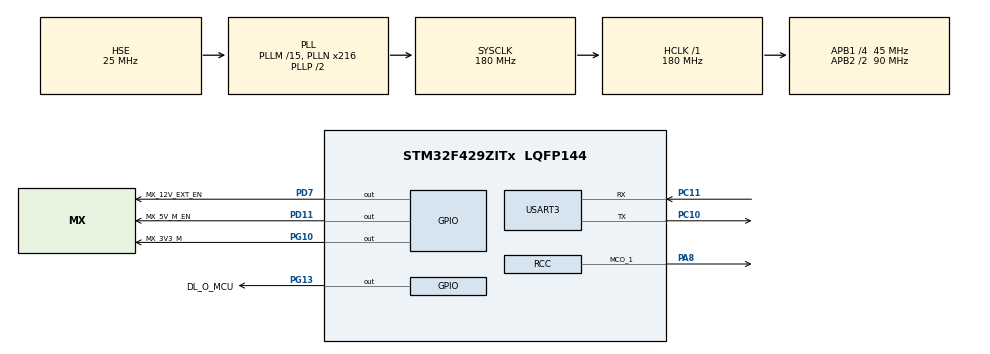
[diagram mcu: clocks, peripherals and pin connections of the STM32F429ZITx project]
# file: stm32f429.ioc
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Mcu.Family=STM32F4
Mcu.Name=STM32F429ZITx
Mcu.Package=LQFP144
NVIC.PriorityGroup=NVIC_PRIORITYGROUP_4
NVIC.TIM6_DAC_IRQn=true\:15\:0\:false\:false\:true\:false\:true
NVIC.TimeBase=TIM6_DAC_IRQn
NVIC.TimeBaseIP=TIM6
NVIC.USART3_IRQn=true\:0\:0\:false\:false\:true\:true\:true
PA13.Mode=Serial_Wire
PA13.Signal=SYS_JTMS-SWDIO
PA14.Mode=Serial_Wire
PA14.Signal=SYS_JTCK-SWCLK
PA8.Mode=Clock-out-1
PA8.Signal=RCC_MCO_1
PC10.Mode=Asynchronous
PC10.Signal=USART3_TX
PC11.Mode=Asynchronous
PC11.Signal=USART3_RX
PD11.GPIO_Label=MX_5V_M_EN
PD11.PinState=GPIO_PIN_SET
PD11.Signal=GPIO_Output
PD7.GPIO_Label=MX_12V_EXT_EN
PD7.PinState=GPIO_PIN_SET
PD7.Signal=GPIO_Output
PG10.GPIO_Label=MX_3V3_M
PG10.GPIO_Speed=GPIO_SPEED_FREQ_LOW
PG10.PinState=GPIO_PIN_SET
PG10.Signal=GPIO_Output
PG13.GPIO_Label=DL_O_MCU
PG13.GPIO_Speed=GPIO_SPEED_FREQ_LOW
PG13.PinState=GPIO_PIN_SET
PG13.Signal=GPIO_Output
PH0/OSC_IN.Mode=HSE-External-Oscillator
PH0/OSC_IN.Signal=RCC_OSC_IN
PH1/OSC_OUT.Mode=HSE-External-Oscillator
PH1/OSC_OUT.Signal=RCC_OSC_OUT
ProjectManager.HeapSize=0x4000
ProjectManager.StackSize=0x1000
ProjectManager.TargetToolchain=Makefile
RCC.48MHZClocksFreq_Value=90000000
RCC.AHBFreq_Value=180000000
RCC.APB1CLKDivider=RCC_HCLK_DIV4
RCC.APB1Freq_Value=45000000
RCC.APB1TimFreq_Value=90000000
RCC.APB2CLKDivider=RCC_HCLK_DIV2
RCC.APB2Freq_Value=90000000
RCC.APB2TimFreq_Value=180000000
RCC.CortexFreq_Value=180000000
RCC.HCLKFreq_Value=180000000
RCC.HSE_VALUE=25000000
RCC.HSI_VALUE=16000000
RCC.LSE_VALUE=32768
RCC.PLLM=15
RCC.PLLN=216
RCC.PLLSourceVirtual=RCC_PLLSOURCE_HSE
RCC.RCC_MCO1Source=RCC_MCO1SOURCE_HSE
RCC.SYSCLKFreq_VALUE=180000000
RCC.SYSCLKSource=RCC_SYSCLKSOURCE_PLLCLK
RCC.VCOOutputFreq_Value=360000000
USART3.VirtualMode=VM_ASYNC
VP_SYS_VS_tim6.Mode=TIM6
board=custom

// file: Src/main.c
/* USER CODE BEGIN Header */
/**
  ******************************************************************************
  * @file           : main.c
  * @brief          : Main program body
  ******************************************************************************
  * @attention
  *
  * Copyright (c) 2021 STMicroelectronics.
  * All rights reserved.
  *
  * This software is licensed under terms that can be found in the LICENSE file
  * in the root directory of this software component.
  * If no LICENSE file comes with this software, it is provided AS-IS.
  *
  ******************************************************************************
  */
/* USER CODE END Header */
#include "main.h"
#include "usart.h"
#include "gpio.h"

/* USER CODE BEGIN Includes */
#include <stdio.h>
#include <errno.h>
#include <sys/unistd.h>
#include "fota_port.h"
// #include <fota_port.h>
/* USER CODE END Includes */

void SystemClock_Config(void);

/* USER CODE BEGIN 0 */
int _write(int file, char *data, int len) {
    HAL_StatusTypeDef status;
    if ((file != STDOUT_FILENO) && (file != STDERR_FILENO)) {
        errno = EBADF;
        return -1;
    }

    status = HAL_UART_Transmit(&FOTA_YMODEM_HUART, (uint8_t *) data, len, 1000);
    return (status == HAL_OK ? len : 0);
}
/* USER CODE END 0 */

int main(void)
{

  /* MCU Configuration--------------------------------------------------------*/

  /* Reset of all peripherals, Initializes the Flash interface and the Systick. */
  HAL_Init();

  /* Configure the system clock */
  SystemClock_Config();

  /* Initialize all configured peripherals */
  MX_GPIO_Init();
  MX_USART3_UART_Init();
  /* USER CODE BEGIN 2 */
  printf("\r\n------START------\r\n");
  /* USER CODE END 2 */
  /* Infinite loop */
  while (1)
  {
    extern void fota_init(void);
    fota_init();
    HAL_Delay(1000);
  }
}

void SystemClock_Config(void)
{
  RCC_OscInitTypeDef RCC_OscInitStruct = {0};
  RCC_ClkInitTypeDef RCC_ClkInitStruct = {0};

  /** Configure the main internal regulator output voltage
  */
  __HAL_RCC_PWR_CLK_ENABLE();
  __HAL_PWR_VOLTAGESCALING_CONFIG(PWR_REGULATOR_VOLTAGE_SCALE1);
  /** Initializes the RCC Oscillators according to the specified parameters
  * in the RCC_OscInitTypeDef structure.
  */
  RCC_OscInitStruct.OscillatorType = RCC_OSCILLATORTYPE_HSE;
  RCC_OscInitStruct.HSEState = RCC_HSE_ON;
  RCC_OscInitStruct.PLL.PLLState = RCC_PLL_ON;
  RCC_OscInitStruct.PLL.PLLSource = RCC_PLLSOURCE_HSE;
  RCC_OscInitStruct.PLL.PLLM = 15;
  RCC_OscInitStruct.PLL.PLLN = 216;
  RCC_OscInitStruct.PLL.PLLP = RCC_PLLP_DIV2;
  RCC_OscInitStruct.PLL.PLLQ = 4;
  if (HAL_RCC_OscConfig(&RCC_OscInitStruct) != HAL_OK)
  {
    Error_Handler();
  }
  /** Activate the Over-Drive mode
  */
  if (HAL_PWREx_EnableOverDrive() != HAL_OK)
  {
    Error_Handler();
  }
  /** Initializes the CPU, AHB and APB buses clocks
  */
  RCC_ClkInitStruct.ClockType = RCC_CLOCKTYPE_HCLK|RCC_CLOCKTYPE_SYSCLK
                              |RCC_CLOCKTYPE_PCLK1|RCC_CLOCKTYPE_PCLK2;
  RCC_ClkInitStruct.SYSCLKSource = RCC_SYSCLKSOURCE_PLLCLK;
  RCC_ClkInitStruct.AHBCLKDivider = RCC_SYSCLK_DIV1;
  RCC_ClkInitStruct.APB1CLKDivider = RCC_HCLK_DIV4;
  RCC_ClkInitStruct.APB2CLKDivider = RCC_HCLK_DIV2;

  if (HAL_RCC_ClockConfig(&RCC_ClkInitStruct, FLASH_LATENCY_5) != HAL_OK)
  {
    Error_Handler();
  }
  HAL_RCC_MCOConfig(RCC_MCO1, RCC_MCO1SOURCE_HSE, RCC_MCODIV_1);
}

void HAL_TIM_PeriodElapsedCallback(TIM_HandleTypeDef *htim)
{
  if (htim->Instance == TIM6) {
    HAL_IncTick();
  }
}

void Error_Handler(void)
{
  __disable_irq();
  while (1)
  {
  }
}
